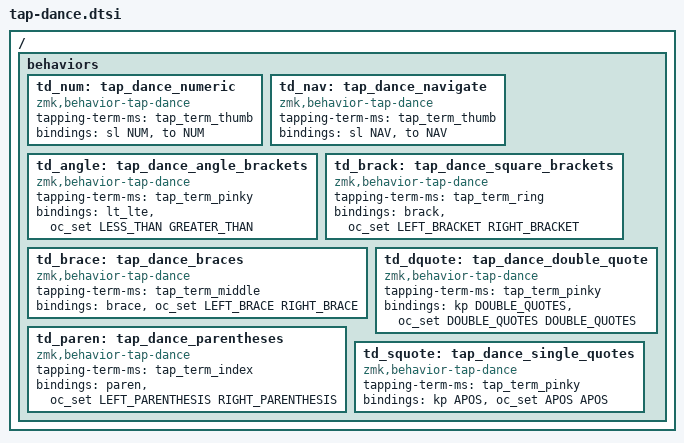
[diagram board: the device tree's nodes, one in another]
/ {
    behaviors {
        td_num: tap_dance_numeric {
            compatible = "zmk,behavior-tap-dance";
            #binding-cells = <0>;
            tapping-term-ms = <tap_term_thumb>;
            bindings = <&sl NUM>, <&to NUM>;
        };

        td_nav: tap_dance_navigate {
            compatible = "zmk,behavior-tap-dance";
            #binding-cells = <0>;
            tapping-term-ms = <tap_term_thumb>;
            bindings = <&sl NAV>, <&to NAV>;
        };

        td_angle: tap_dance_angle_brackets {
            compatible = "zmk,behavior-tap-dance";
            #binding-cells = <0>;
            tapping-term-ms = <tap_term_pinky>;
            bindings = <&lt_lte>, <&oc_set LESS_THAN GREATER_THAN>;
        };

        td_brack: tap_dance_square_brackets {
            compatible = "zmk,behavior-tap-dance";
            #binding-cells = <0>;
            tapping-term-ms = <tap_term_ring>;
            bindings = <&brack>, <&oc_set LEFT_BRACKET RIGHT_BRACKET>;
        };

        td_brace: tap_dance_braces {
            compatible = "zmk,behavior-tap-dance";
            #binding-cells = <0>;
            tapping-term-ms = <tap_term_middle>;
            bindings = <&brace>, <&oc_set LEFT_BRACE RIGHT_BRACE>;
        };

        td_paren: tap_dance_parentheses {
            compatible = "zmk,behavior-tap-dance";
            #binding-cells = <0>;
            tapping-term-ms = <tap_term_index>;
            bindings = <&paren>, <&oc_set LEFT_PARENTHESIS RIGHT_PARENTHESIS>;
        };

        td_dquote: tap_dance_double_quote {
            compatible = "zmk,behavior-tap-dance";
            #binding-cells = <0>;
            tapping-term-ms = <tap_term_pinky>;
            bindings = <&kp DOUBLE_QUOTES>, <&oc_set DOUBLE_QUOTES DOUBLE_QUOTES>;
        };

        td_squote: tap_dance_single_quotes {
            compatible = "zmk,behavior-tap-dance";
            #binding-cells = <0>;
            tapping-term-ms = <tap_term_pinky>;
            bindings = <&kp APOS>, <&oc_set APOS APOS>;
        };
    };
};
